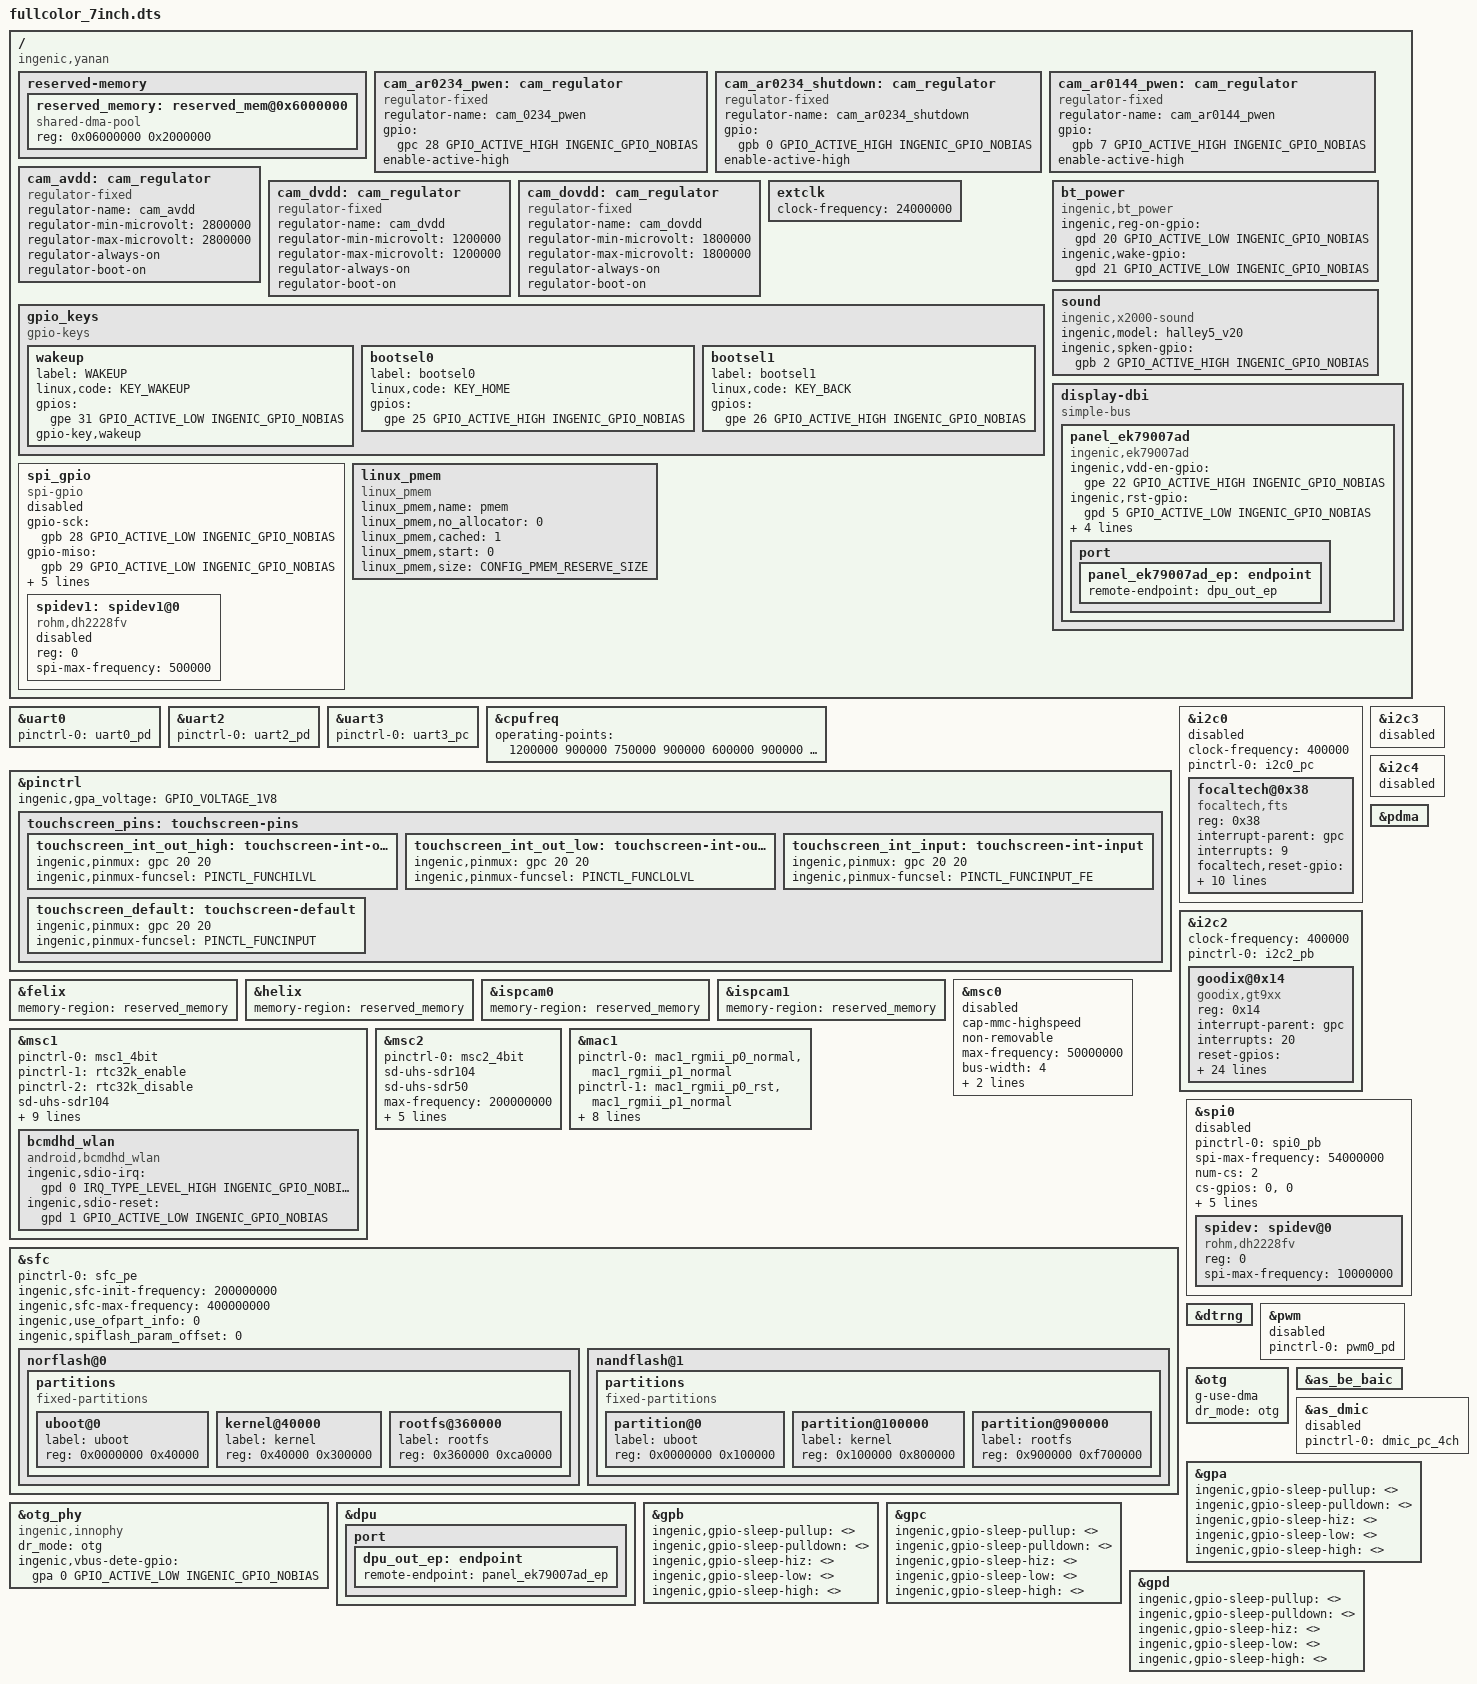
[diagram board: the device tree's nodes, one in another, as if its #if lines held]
/dts-v1/;

#include <dt-bindings/input/input.h>
#include "x2000-v12.dtsi"
#include <dt-bindings/interrupt-controller/irq.h>
#include <generated/autoconf.h>

/ {
	compatible = "ingenic,yanan", "ingenic,x2000-v12";

	/*chosen {
		bootargs = "console=ttyS1,115200 mem=128M@0x0ip=off init=/linuxrc ubi.mtd=3 root=ubi0:rootfs ubi.mtd=4 rootfstype=ubifs rw";
	};*/

	reserved-memory {
		#address-cells = <1>;
		#size-cells = <1>;
		ranges =<>;

		reserved_memory: reserved_mem@0x6000000{
		      compatible = "shared-dma-pool";
		      reg = <0x06000000 0x2000000>;
		};
	};

#ifdef CONFIG_RD_X2000_HALLEY5_CAMERA_1V0
		  cam_ar0234_pwen: cam_regulator {
			  compatible = "regulator-fixed";
			  regulator-name = "cam_0234_pwen";
			  gpio = <&gpc 28 GPIO_ACTIVE_HIGH INGENIC_GPIO_NOBIAS>;
			  enable-active-high;
		  };
		  cam_ar0234_shutdown: cam_regulator {
			  compatible = "regulator-fixed";
			  regulator-name = "cam_ar0234_shutdown";
			  gpio = <&gpb 0 GPIO_ACTIVE_HIGH INGENIC_GPIO_NOBIAS>;
			  enable-active-high;
		  };
		  cam_ar0144_pwen: cam_regulator {
			  compatible = "regulator-fixed";
			  regulator-name = "cam_ar0144_pwen";
	   		  gpio = <&gpb 7 GPIO_ACTIVE_HIGH INGENIC_GPIO_NOBIAS>;
			  enable-active-high;
		  };
#endif

		  cam_avdd: cam_regulator {
			  compatible = "regulator-fixed";
			  regulator-name = "cam_avdd";
			  regulator-min-microvolt = <2800000>;
			  regulator-max-microvolt = <2800000>;
			  regulator-always-on;
			  regulator-boot-on;
		  };
		  cam_dvdd: cam_regulator {
			  compatible = "regulator-fixed";
			  regulator-name = "cam_dvdd";
			  regulator-min-microvolt = <1200000>;
			  regulator-max-microvolt = <1200000>;
			  regulator-always-on;
			  regulator-boot-on;
		  };
		  cam_dovdd: cam_regulator {
			   compatible = "regulator-fixed";
			   regulator-name = "cam_dovdd";
			   regulator-min-microvolt = <1800000>;
			   regulator-max-microvolt = <1800000>;
			   regulator-always-on;
			   regulator-boot-on;
		  };
};

&uart0 {
	status = "okay";
	pinctrl-names = "default";
	pinctrl-0 = <&uart0_pd>;
};

&uart2 {
	status = "okay";
	pinctrl-names = "default";
	pinctrl-0 = <&uart2_pd>;
};

&uart3 {
	status = "okay";
	pinctrl-names = "default";
	pinctrl-0 = <&uart3_pc>;
};

&cpufreq {
	status = "okay";
	operating-points = <
		/*KHZ uV */
		1200000	900000
		750000	900000
		600000	900000
		500000	900000
		400000	900000
		375000	900000
		300000	900000
		200000	900000
			>;

};

&pinctrl {
	ingenic,gpa_voltage = <GPIO_VOLTAGE_1V8>;
};

&i2c0 {
	clock-frequency = <400000>;
	pinctrl-names = "default";
	status = "disable";
	pinctrl-0 = <&i2c0_pc>;

	focaltech@0x38{
		compatible = "focaltech,fts"; /* do not modify */
		reg = <0x38>; /* do not modify */
		interrupt-parent = <&gpc>; /* INT pin */
		interrupts = <9>;
		focaltech,reset-gpio = <&gpc 8 GPIO_ACTIVE_LOW INGENIC_GPIO_NOBIAS>; /* RST pin */
		focaltech,irq-gpio = <&gpc 9 IRQ_TYPE_EDGE_FALLING INGENIC_GPIO_NOBIAS>; /* INT pin */
		focaltech,max-touch-number = <5>;
		focaltech,display-coords = <0 0 1080 1920>;	/* resolution */

		/* key settings */
		focaltech,have-key;
		focaltech,key-number = <3>;
		focaltech,keys = <139 172 158>; /* key codes*/
		focaltech,key-x-coords = <200 600 800>; /* keys x coords */
		focaltech,key-y-coords = <2000 2000 2000>; /* keys y coords */

	};

};

&pinctrl {
	touchscreen_pins:touchscreen-pins {
		touchscreen_int_out_high:touchscreen-int-out-high {
			ingenic,pinmux = <&gpc 20 20>;
			ingenic,pinmux-funcsel = <PINCTL_FUNCHILVL>;
		};
		touchscreen_int_out_low:touchscreen-int-out-low {
			ingenic,pinmux = <&gpc 20 20>;
			ingenic,pinmux-funcsel = <PINCTL_FUNCLOLVL>;
		};
		touchscreen_int_input:touchscreen-int-input {
			ingenic,pinmux = <&gpc 20 20>;
			ingenic,pinmux-funcsel = <PINCTL_FUNCINPUT_FE>;
		};
		touchscreen_default:touchscreen-default {
			ingenic,pinmux = <&gpc 20 20>;
			ingenic,pinmux-funcsel = <PINCTL_FUNCINPUT>;
		};
	};
};

&i2c2 {
	clock-frequency = <400000>;
	pinctrl-names = "default";
	status = "okay";
	pinctrl-0 = <&i2c2_pb>;

	goodix@0x14{
		compatible = "goodix,gt9xx"; /* do not modify */
		reg = <0x14>; /* do not modify */
		interrupt-parent = <&gpc>; /* INT pin */
		interrupts = <20>;
		reset-gpios = <&gpc 21 GPIO_ACTIVE_LOW INGENIC_GPIO_NOBIAS>; /* RST pin */
		irq-gpios = <&gpc 20 IRQ_TYPE_EDGE_FALLING INGENIC_GPIO_NOBIAS>; /* INT pin */
		gt9xx,max-touch-number = <5>;
		gt9xx,display-coords = <0 0 1080 600>;	/* resolution */

		touchscreen-size-x = <1024>;
		touchscreen-size-y = <600>;
	//	touchscreen-max-w = <1024>;
	//	touchscreen-max-p = <1024>;

		goodix,slide-wakeup = <0>;
		goodix,type-a-report = <0>;
		goodix,driver-send-cfg = <1>;
		goodix,resume-in-workqueue = <0>;
		goodix,int-sync = <1>;
		goodix,swap-x2y = <0>;
		goodix,esd-protect = <1>;
		goodix,auto-update-cfg = <0>;
		goodix,power-off-sleep = <0>;
		goodix,pen-suppress-finger = <0>;
		irq-flags = <2>; /* 1 rising, 2 falling */
		pinctrl-names = "default", "int-output-high", "int-output-low", "int-input";
		pinctrl-0 = <&touchscreen_default>;
		pinctrl-1 = <&touchscreen_int_out_high>;
		pinctrl-2 = <&touchscreen_int_out_low>;
		pinctrl-3 = <&touchscreen_int_input>;
		goodix,cfg-group3 = [
			5F 00 04 58 02 05 FD 00 01 48 28 0D 50 32 03 05 00 00
			00 00 00 00 00 18 1A 1E 14 8A 2A 0C 30 38 31 0D 00 00
			00 D9 03 2D 00 00 00 00 00 03 64 32 00 00 00 1D 41 94
			C5 02 07 00 00 04 A5 1F 00 94 25 00 88 2B 00 7D 33 00
			74 3C 00 74 00 00 00 00 00 00 00 00 00 00 00 00 00 00
			00 00 00 00 00 00 00 00 00 00 00 00 00 00 00 00 00 00
			00 00 00 00 18 16 14 12 10 0E 0C 0A 08 06 04 02 FF FF
			00 00 00 00 00 00 00 00 00 00 00 00 00 00 00 00 24 22
			21 20 1F 1E 1D 1C 18 16 13 12 10 0F 0A 08 06 04 02 00
			FF FF FF FF FF FF 00 00 00 00 00 00 00 00 00 00 00 00
			00 00 00 00 E4 01
		];

	};

};

&i2c3 {
	status = "disable";
};

&i2c4 {
	status = "disable";
};


&felix {
	status = "okay";
	memory-region=<&reserved_memory>;
};

&helix {
	status = "okay";
	memory-region=<&reserved_memory>;
};

&ispcam0 {
	status = "okay";
	memory-region=<&reserved_memory>;
};

&ispcam1 {
	status = "okay";
	memory-region=<&reserved_memory>;
};

&pdma {
	status = "okay";
};

&msc0 {
	status = "disable";
	/*mmc-hs200-1_8v;*/
	cap-mmc-highspeed;
	non-removable;
	max-frequency = <50000000>;
	bus-width = <4>;
	non-removable;
	voltage-ranges = <1800 3300>;

	/* special property */
	ingenic,rst-gpios = <0>;
};

&msc1 {
	status = "okay";
	pinctrl-names ="default","enable", "disable";
	pinctrl-0 = <&msc1_4bit>;
	pinctrl-1 = <&rtc32k_enable>;
	pinctrl-2 = <&rtc32k_disable>;

	sd-uhs-sdr104;
	max-frequency = <100000000>;
	bus-width = <4>;
	voltage-ranges = <1800 3300>;
	non-removable;

	ingenic,sdio_clk = <1>;
	keep-power-in-suspend;

	/* special property */
	ingenic,sdr-gpios = <0>;
	ingenic,rst-gpios = <0>;
	ingenic,removal-manual; /*removal-dontcare, removal-nonremovable, removal-removable, removal-manual*/

	bcmdhd_wlan: bcmdhd_wlan {
		 compatible = "android,bcmdhd_wlan";
		 ingenic,sdio-irq = <&gpd 0 IRQ_TYPE_LEVEL_HIGH INGENIC_GPIO_NOBIAS>;
		 ingenic,sdio-reset = <&gpd 1 GPIO_ACTIVE_LOW INGENIC_GPIO_NOBIAS>;
	};
};

&msc2 {
	status = "okay";
	pinctrl-names ="default";
	pinctrl-0 = <&msc2_4bit>;
	sd-uhs-sdr104;
	sd-uhs-sdr50;
	/* cd-inverted; */
	max-frequency = <200000000>;
	bus-width = <4>;
	voltage-ranges = <1800 3300>;

	cd-gpios = <&gpc 22 GPIO_ACTIVE_LOW INGENIC_GPIO_NOBIAS>;
	/* special property */
//	ingenic,sdr-gpios = <&gpc 0 GPIO_ACTIVE_HIGH INGENIC_GPIO_NOBIAS>;
	ingenic,rst-gpios = <0>;
};


&mac1 {
	pinctrl-names = "default", "reset";
	pinctrl-0 = <&mac1_rgmii_p0_normal>, <&mac1_rgmii_p1_normal>;
	pinctrl-1 = <&mac1_rgmii_p0_rst>, <&mac1_rgmii_p1_normal>;
	status = "okay";
	ingenic,rst-gpio = <&gpb 16 GPIO_ACTIVE_LOW INGENIC_GPIO_NOBIAS>;
	ingenic,rst-ms = <10>;
	ingenic,rst-delay-ms = <15>;
	ingenic,mac-mode = <RGMII>;
	ingenic,mode-reg = <0xb00000e8>;
	ingenic,rx-clk-delay = <0x0>;
	ingenic,tx-clk-delay = <0x3f>;
};

&sfc {
	status = "okay";
	pinctrl-names = "default";
	pinctrl-0 = <&sfc_pe>;
	ingenic,sfc-init-frequency = <200000000>;
	ingenic,sfc-max-frequency = <400000000>;
	ingenic,use_ofpart_info  = /bits/ 8 <0>;
	ingenic,spiflash_param_offset = <0>;

	norflash@0 {
		partitions {
			compatible = "fixed-partitions";
			#address-cells = <1>;
			#size-cells = <1>;

			/* spi nor flash partition */
			uboot@0 {
				label = "uboot";
				reg = <0x0000000 0x40000>;
				/*read-only;*/
			};

			kernel@40000 {
				label = "kernel";
				reg = <0x40000 0x300000>;
			};

			rootfs@360000 {
				label = "rootfs";
				reg = <0x360000 0xca0000>;
			};
		};
	};

	nandflash@1 {
		partitions {
			compatible = "fixed-partitions";
			#address-cells = <1>;
			#size-cells = <1>;

			/* spi nand flash partition */
			partition@0 {
				label = "uboot";
				reg = <0x0000000 0x100000>;
				/*read-only;*/
			};

			partition@100000 {
				label = "kernel";
				reg = <0x100000 0x800000>;
			};

			partition@900000 {
				label = "rootfs";
				reg = <0x900000 0xf700000>;
			};
		};
	};

};

&spi0 {
	status = "disable";
	pinctrl-names = "default";
	pinctrl-0 = <&spi0_pb>;

	spi-max-frequency = <54000000>;
	num-cs = <2>;
	cs-gpios = <0>, <0>;
	/*cs-gpios = <&gpa 27 GPIO_ACTIVE_HIGH INGENIC_GPIO_NOBIAS>, <&gpa 27 GPIO_ACTIVE_HIGH INGENIC_GPIO_NOBIAS>;*/
	ingenic,chnl = <0>;
	ingenic,allow_cs_same = <1>;
	ingenic,bus_num = <0>;
	ingenic,has_dma_support = <0>;
	ingenic,spi-src-clk = <1>;/*0.ext; 1.ssi*/

	/* Add SPI interface device */
	spidev: spidev@0 {
		compatible = "rohm,dh2228fv";
		reg = <0>;
		spi-max-frequency = <10000000>;
	};
};

&dtrng {
	status = "okay";
};

&pwm {
	pinctrl-names = "default";
	pinctrl-0 = <&pwm0_pd>;
/*	pinctrl-0 = <&pwm1_pc>; */
	status = "disable";
};

&otg {
	g-use-dma;
	dr_mode = "otg";
	status = "okay";
};

&otg_phy {
	dr_mode = "otg";
	compatible = "ingenic,innophy", "syscon";
    ingenic,vbus-dete-gpio = <&gpa 0 GPIO_ACTIVE_LOW INGENIC_GPIO_NOBIAS>;
	/*ingenic,drvvbus-gpio = <&gpe 22 GPIO_ACTIVE_HIGH INGENIC_GPIO_NOBIAS>;*/
	status = "okay";
};

&as_be_baic {
	pinctrl-names = "default";
//	pinctrl-0 =  <&baic4_pd>;
};

&as_dmic {
	pinctrl-names = "default";
	pinctrl-0 = <&dmic_pc_4ch>;
	status = "disable";
};

&dpu {
	status = "okay";
	port {
		dpu_out_ep: endpoint {
			remote-endpoint = <&panel_ek79007ad_ep>;
	    };
	};

};

/ {

	extclk: extclk {
		clock-frequency = <24000000>;
	};

	gpio_keys: gpio_keys {
		   compatible = "gpio-keys";

		   wakeup {
			   label = "WAKEUP";
			   linux,code = <KEY_WAKEUP>;
			   gpios = <&gpe 31 GPIO_ACTIVE_LOW INGENIC_GPIO_NOBIAS>;
			   gpio-key,wakeup;
		   };

		   bootsel0 {
			   label = "bootsel0";
			   linux,code = <KEY_HOME>;
			   gpios = <&gpe 25 GPIO_ACTIVE_HIGH INGENIC_GPIO_NOBIAS>;
		   };

		   bootsel1 {
			   label = "bootsel1";
			   linux,code = <KEY_BACK>;
			   gpios = <&gpe 26 GPIO_ACTIVE_HIGH INGENIC_GPIO_NOBIAS>;
		   };
	   };

	/*
	 * gpd 21 bt wakeup host
	 * gpd 22 host wakeup bt
	 */
	bt_power {
		compatible = "ingenic,bt_power";
		ingenic,reg-on-gpio = <&gpd 20 GPIO_ACTIVE_LOW INGENIC_GPIO_NOBIAS>;
		ingenic,wake-gpio = <&gpd 21 GPIO_ACTIVE_LOW INGENIC_GPIO_NOBIAS>;
	};

	sound {
		compatible = "ingenic,x2000-sound";
		ingenic,model = "halley5_v20";
		ingenic,spken-gpio = <&gpb 2 GPIO_ACTIVE_HIGH INGENIC_GPIO_NOBIAS>;
	};

	display-dbi {
		compatible = "simple-bus";
		#interrupt-cells = <1>;
		#address-cells = <1>;
		#size-cells = <1>;
		ranges = <>;
		panel_ek79007ad {
			compatible = "ingenic,ek79007ad";
			status = "okay";
			pinctrl-names = "default";
			ingenic,vdd-en-gpio = <&gpe 22 GPIO_ACTIVE_HIGH INGENIC_GPIO_NOBIAS>;
			ingenic,rst-gpio = <&gpd 5 GPIO_ACTIVE_LOW INGENIC_GPIO_NOBIAS>;
			ingenic,stbyb-gpio = <&gpd 4 GPIO_ACTIVE_HIGH INGENIC_GPIO_NOBIAS>;
			ingenic,lcd-pwm-gpio = <&gpd 31 GPIO_ACTIVE_LOW INGENIC_GPIO_NOBIAS>;
			port {
				panel_ek79007ad_ep: endpoint {
					remote-endpoint = <&dpu_out_ep>;
				};
			};
		};
	};
/*	backlight {
		compatible = "pwm-backlight";
		pwms = <&pwm 1 1000000>;
		brightness-levels = <0 1 2 3 4 5 6 7 8 9 10 11 12 13 14 15>;
		default-brightness-level = <4>;
	};
*/

	spi_gpio {
		status = "disable";
		compatible = "spi-gpio";
		#address-cells = <1>;
		#size-cells = <0>;

		gpio-sck = <&gpb 28 GPIO_ACTIVE_LOW INGENIC_GPIO_NOBIAS>;
		gpio-miso = <&gpb 29 GPIO_ACTIVE_LOW INGENIC_GPIO_NOBIAS>;
		gpio-mosi = <&gpb 30 GPIO_ACTIVE_LOW INGENIC_GPIO_NOBIAS>;
		cs-gpios = <&gpb 31 GPIO_ACTIVE_LOW INGENIC_GPIO_NOBIAS>;
		num-chipselects = <1>;

		/* clients */
		spidev1: spidev1@0 {
			status = "disable";
			compatible = "rohm,dh2228fv";
			reg = <0>;
			spi-max-frequency = <500000>;
		};
	};
#ifdef CONFIG_LINUX_PMEM
	linux_pmem {
		status = "ok";
		compatible = "linux_pmem";
		linux_pmem,name = "pmem";
		linux_pmem,no_allocator = <0>;
		linux_pmem,cached       = <1>;
		linux_pmem,start        = <0>;
		linux_pmem,size         = CONFIG_PMEM_RESERVE_SIZE;
    };
#endif
};


/* Board Sleep GPIO configuration. */
/* <0 1 2 3 .... 31>, set one of the pin to state.*/
&gpa {
	ingenic,gpio-sleep-pullup 	= <>;
	ingenic,gpio-sleep-pulldown 	= <>;
	ingenic,gpio-sleep-hiz		= <>;
	ingenic,gpio-sleep-low		= <>;
	ingenic,gpio-sleep-high		= <>;
};

&gpb {
	ingenic,gpio-sleep-pullup 	= <>;
	ingenic,gpio-sleep-pulldown 	= <>;
	ingenic,gpio-sleep-hiz		= <>;
	ingenic,gpio-sleep-low		= <>;
	ingenic,gpio-sleep-high		= <>;
};

&gpc {
	ingenic,gpio-sleep-pullup 	= <>;
	ingenic,gpio-sleep-pulldown 	= <>;
	ingenic,gpio-sleep-hiz		= <>;
	ingenic,gpio-sleep-low		= <>;
	ingenic,gpio-sleep-high		= <>;
};

&gpd {
	ingenic,gpio-sleep-pullup 	= <>;
	ingenic,gpio-sleep-pulldown 	= <>;
	ingenic,gpio-sleep-hiz		= <>;
	ingenic,gpio-sleep-low		= <>;
	ingenic,gpio-sleep-high		= <>;
};
